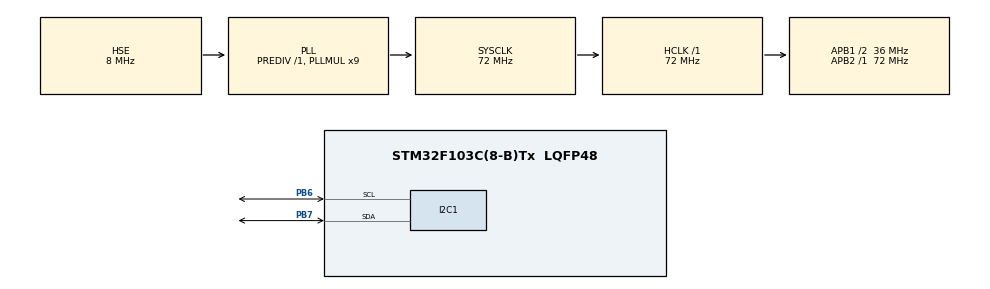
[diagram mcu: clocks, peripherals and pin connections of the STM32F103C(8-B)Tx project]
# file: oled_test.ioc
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Mcu.Family=STM32F1
Mcu.Name=STM32F103C(8-B)Tx
Mcu.Package=LQFP48
NVIC.PriorityGroup=NVIC_PRIORITYGROUP_4
PA13.Mode=Serial_Wire
PA13.Signal=SYS_JTMS-SWDIO
PA14.Mode=Serial_Wire
PA14.Signal=SYS_JTCK-SWCLK
PB6.Mode=I2C
PB6.Signal=I2C1_SCL
PB7.Mode=I2C
PB7.Signal=I2C1_SDA
PD0-OSC_IN.Mode=HSE-External-Oscillator
PD0-OSC_IN.Signal=RCC_OSC_IN
PD1-OSC_OUT.Mode=HSE-External-Oscillator
PD1-OSC_OUT.Signal=RCC_OSC_OUT
ProjectManager.HeapSize=0x200
ProjectManager.StackSize=0x400
ProjectManager.TargetToolchain=MDK-ARM V5.32
RCC.AHBFreq_Value=72000000
RCC.APB1CLKDivider=RCC_HCLK_DIV2
RCC.APB1Freq_Value=36000000
RCC.APB1TimFreq_Value=72000000
RCC.APB2Freq_Value=72000000
RCC.APB2TimFreq_Value=72000000
RCC.HCLKFreq_Value=72000000
RCC.PLLMUL=RCC_PLL_MUL9
RCC.PLLSourceVirtual=RCC_PLLSOURCE_HSE
RCC.SYSCLKFreq_VALUE=72000000
RCC.SYSCLKSource=RCC_SYSCLKSOURCE_PLLCLK
RCC.USBFreq_Value=72000000
board=custom

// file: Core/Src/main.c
/* USER CODE BEGIN Header */
/**
  ******************************************************************************
  * @file           : main.c
  * @brief          : Main program body
  ******************************************************************************
  * @attention
  *
  * Copyright (c) 2026 STMicroelectronics.
  * All rights reserved.
  *
  * This software is licensed under terms that can be found in the LICENSE file
  * in the root directory of this software component.
  * If no LICENSE file comes with this software, it is provided AS-IS.
  *
  ******************************************************************************
  */
/* USER CODE END Header */
#include "main.h"
#include "i2c.h"
#include "gpio.h"
#include "oled_picture.h"

/* USER CODE BEGIN PV */
void Oled_Write_Cmd(uint8_t dataCmd) {
    HAL_I2C_Mem_Write(&hi2c1, 0x78, 0x00, I2C_MEMADD_SIZE_8BIT,
                      &dataCmd, 1, 0xff); // 0x78是设备地址 1 发送数据的长度,1个字节
}

void Oled_Write_Data(uint8_t dataData) {
    HAL_I2C_Mem_Write(&hi2c1, 0x78, 0x40, I2C_MEMADD_SIZE_8BIT,
                      &dataData, 1, 0xff); // 0x78是设备地址 1 发送数据的长度,1个字节
}

void Oled_Init(void)
{
    Oled_Write_Cmd(0xAE); //--display off
    Oled_Write_Cmd(0x00); //--set low column address
    Oled_Write_Cmd(0x10); //--set high column address
    Oled_Write_Cmd(0x40); //--set start line address
    Oled_Write_Cmd(0xB0); //--set page address
    Oled_Write_Cmd(0x81); // contract control
    Oled_Write_Cmd(0xFF); //--128
    Oled_Write_Cmd(0xA1); //set segment remap
    Oled_Write_Cmd(0xA6); //--normal / reverse
    Oled_Write_Cmd(0xA8); //--set multiplex ratio(1 to 64)
    Oled_Write_Cmd(0x3F); //--1/32 duty
    Oled_Write_Cmd(0xC8); //Com scan direction
    Oled_Write_Cmd(0xD3); //-set display offset
    Oled_Write_Cmd(0x00); //

    Oled_Write_Cmd(0xD5); //set osc division
    Oled_Write_Cmd(0x80); //

    Oled_Write_Cmd(0xD8); //set area color mode off
    Oled_Write_Cmd(0x05); //

    Oled_Write_Cmd(0xD9); //Set Pre‑Charge Period
    Oled_Write_Cmd(0xF1); //

    Oled_Write_Cmd(0xDA); //set com pin configuartion
    Oled_Write_Cmd(0x12); //

    Oled_Write_Cmd(0xDB); //set Vcomh
    Oled_Write_Cmd(0x30); //

    Oled_Write_Cmd(0x8D); //set charge pump enable
    Oled_Write_Cmd(0x14); //

    Oled_Write_Cmd(0xAF); //--turn on oled panel
}

void Oled_Clear(void)
{
    uint8_t page;
    uint8_t col;

    // 设置为页寻址模式
    Oled_Write_Cmd(0x20);
    Oled_Write_Cmd(0x02);

    // 8 页，每页 128 列，全部写 0
    for (page = 0; page < 8; page++)
    {
        Oled_Write_Cmd(0xB0 + page);
        Oled_Write_Cmd(0x00);  // 列地址低 4 位
        Oled_Write_Cmd(0x10);  // 列地址高 4 位

        for (col = 0; col < 128; col++)
        {
            Oled_Write_Data(0x00);
        }
    }

    // 写入位置恢复到第 0 页、第 0 列
    Oled_Write_Cmd(0xB0);
    Oled_Write_Cmd(0x00);
    Oled_Write_Cmd(0x10);
}

/* USER CODE END PV */

void SystemClock_Config(void);

  int main(void)
{

  /* MCU Configuration--------------------------------------------------------*/

  /* Reset of all peripherals, Initializes the Flash interface and the Systick. */
  HAL_Init();

  /* Configure the system clock */
  SystemClock_Config();

  /* Initialize all configured peripherals */
  MX_GPIO_Init();
  MX_I2C1_Init();
  /* USER CODE BEGIN 2 */

HAL_Delay(100);
Oled_Init();
Oled_ShowPicture();

  /* USER CODE END 2 */

  /* Infinite loop */
  while (1)
  {

  }
}

void SystemClock_Config(void)
{
  RCC_OscInitTypeDef RCC_OscInitStruct = {0};
  RCC_ClkInitTypeDef RCC_ClkInitStruct = {0};

  /** Initializes the RCC Oscillators according to the specified parameters
  * in the RCC_OscInitTypeDef structure.
  */
  RCC_OscInitStruct.OscillatorType = RCC_OSCILLATORTYPE_HSE;
  RCC_OscInitStruct.HSEState = RCC_HSE_ON;
  RCC_OscInitStruct.HSEPredivValue = RCC_HSE_PREDIV_DIV1;
  RCC_OscInitStruct.HSIState = RCC_HSI_ON;
  RCC_OscInitStruct.PLL.PLLState = RCC_PLL_ON;
  RCC_OscInitStruct.PLL.PLLSource = RCC_PLLSOURCE_HSE;
  RCC_OscInitStruct.PLL.PLLMUL = RCC_PLL_MUL9;
  if (HAL_RCC_OscConfig(&RCC_OscInitStruct) != HAL_OK)
  {
    Error_Handler();
  }

  /** Initializes the CPU, AHB and APB buses clocks
  */
  RCC_ClkInitStruct.ClockType = RCC_CLOCKTYPE_HCLK|RCC_CLOCKTYPE_SYSCLK
                              |RCC_CLOCKTYPE_PCLK1|RCC_CLOCKTYPE_PCLK2;
  RCC_ClkInitStruct.SYSCLKSource = RCC_SYSCLKSOURCE_PLLCLK;
  RCC_ClkInitStruct.AHBCLKDivider = RCC_SYSCLK_DIV1;
  RCC_ClkInitStruct.APB1CLKDivider = RCC_HCLK_DIV2;
  RCC_ClkInitStruct.APB2CLKDivider = RCC_HCLK_DIV1;

  if (HAL_RCC_ClockConfig(&RCC_ClkInitStruct, FLASH_LATENCY_2) != HAL_OK)
  {
    Error_Handler();
  }
}

void Error_Handler(void)
{
  __disable_irq();
  while (1)
  {
  }
}
